# M367 register map
File version: 0.1
TOSHIBA Cortex-M3 MCU
Registers are 32-bit, read-write, reset 0x0 unless marked. A register's access mark holds for its fields unless they carry their own. Offsets are from the block's base; lines under a group give offsets from that group; [hi:lo] are bit positions; {n}, {i} and the like mark numbered series; 'fields as' and 'values as' point back to an identical list; <NAME> marks a mode.

## Memory map
0x40008000 UDFS blocks up to offset 0x8C — UDC2 AHB Bridge
0x40008200 UDFS2 blocks up to offset 0x338 — UDC2(USB -Spec2.0 Device contoller)
0x40040000 SSP0 size 0x28 — Synchronous Serial Port
0x40041000 SSP1 size 0x28
0x40042000 SSP2 size 0x28
0x40048000 UART4 blocks up to offset 0x4C — ARM Prime Cell PL011
0x40049000 UART5 blocks up to offset 0x4C
0x4004C000 DMAA blocks up to offset 0x50 — DMA Controller
0x4004D000 DMAB blocks up to offset 0x50
0x40050000 ADA blocks up to offset 0x78 — Analog-to-Digital Converter (AD)
0x40051000 ADB blocks up to offset 0x78 — Analog-to-Digital Converter (AD)
0x40052000 ADILV size 0xC — Dual ADC Configuration
0x40054000 DA0 size 0x14 — Digital-to-Analog Converter (DA)
0x40055000 DA1 size 0x14
0x4005C000 EXB blocks up to offset 0x50 — External Bus Interface(EXB)
0x400C0000 PA blocks up to offset 0x3C — General Purpose Input_Output Port (PA)
0x400C0100 PB blocks up to offset 0x3C — General Purpose Input_Output Port (PB)
0x400C0400 PE blocks up to offset 0x3C — General Purpose Input_Output Port (PE)
0x400C0500 PF blocks up to offset 0x3C — General Purpose Input_Output Port (PF)
0x400C0600 PG blocks up to offset 0x3C — General Purpose Input_Output Port (PG)
0x400C0700 PH blocks up to offset 0x3C — General Purpose Input_Output Port (PH)
0x400C0800 PI blocks up to offset 0x3C — General Purpose Input_Output Port (PI)
0x400C0A00 PK blocks up to offset 0x3C — General Purpose Input_Output Port (PK)
0x400C0B00 PL blocks up to offset 0x3C — General Purpose Input_Output Port (PL)
0x400C4000 TB0 size 0x34 — 16-bit Timer_Event Counter (TB)
0x400C4100 TB1 size 0x34
0x400C4200 TB2 size 0x34
0x400C4300 TB3 size 0x34
0x400C4400 TB4 size 0x34
0x400C4500 TB5 size 0x34
0x400C4600 TB6 size 0x34
0x400C4700 TB7 size 0x34
0x400C7000 MT0 size 0x58 — 16-bit Multi-Purpose Timer (MPT-TMR_IGBT)
0x400C7100 MT1 size 0x58
0x400C7200 MT2 size 0x58
0x400C7300 MT3 size 0x58
0x400CC000 RTC blocks up to offset 0xD — Real Time Clock (RTC)
0x400E0000 SBI0 size 0x18 — Serial Bus Interface (SBI)
0x400E0100 SBI1 size 0x18
0x400E0200 SBI2 size 0x18
0x400E1000 SC0 size 0x34 — Serial Channel (SC)
0x400E1100 SC1 size 0x34
0x400E1200 SC2 size 0x34
0x400E1300 SC3 size 0x34
0x400E7000 RMC size 0x38 — Remote Control Signal Preprocessor (RMC)
0x400F1000 OFD size 0x24 — Oscillation Frequency Detector (OFD)
0x400F2000 WD size 0x8 — Watchdog Timer (WD)
0x400F3000 CG blocks up to offset 0x6C — Clock Generator (CG)
0x400F3100 USBPLL size 0xC — Low Voltage detector control register
0x400F3200 TRMOSC size 0x10 — Low Voltage detector control register
0x400F4000 LVD size 0xC — Low Voltage detector control register
0x400F6000 MTPD blocks up to offset 0x48 — 16-bit Multi-Purpose Timer (MPT-PMD)
0x400F7000 EN size 0x10 — Encoder Input (ENC)
0x41FFF000 FC blocks up to offset 0x24 — Flash Control (FC)

## UDFS — UDC2 AHB Bridge
Base 0x40008000
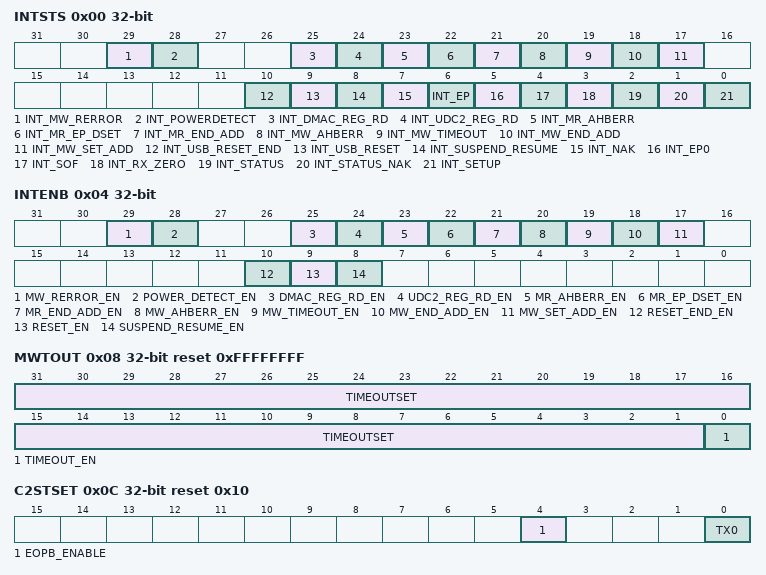
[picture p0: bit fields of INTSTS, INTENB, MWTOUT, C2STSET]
0x00 INTSTS — Interrupt Status Register
  [29] INT_MW_RERROR, [28] INT_POWERDETECT, [25] INT_DMAC_REG_RD, [24] INT_UDC2_REG_RD, [23] INT_MR_AHBERR, [22] INT_MR_EP_DSET, [21] INT_MR_END_ADD, [20] INT_MW_AHBERR, [19] INT_MW_TIMEOUT, [18] INT_MW_END_ADD, [17] INT_MW_SET_ADD, [10] INT_USB_RESET_END, [9] INT_USB_RESET, [8] INT_SUSPEND_RESUME, [7] INT_NAK ro, [6] INT_EP ro, [5] INT_EP0 ro, [4] INT_SOF ro, [3] INT_RX_ZERO ro, [2] INT_STATUS ro, [1] INT_STATUS_NAK ro, [0] INT_SETUP ro
0x04 INTENB — Interrupt Enable Register
  [29] MW_RERROR_EN, [28] POWER_DETECT_EN, [25] DMAC_REG_RD_EN, [24] UDC2_REG_RD_EN, [23] MR_AHBERR_EN, [22] MR_EP_DSET_EN, [21] MR_END_ADD_EN, [20] MW_AHBERR_EN, [19] MW_TIMEOUT_EN, [18] MW_END_ADD_EN, [17] MW_SET_ADD_EN, [10] RESET_END_EN, [9] RESET_EN, [8] SUSPEND_RESUME_EN
0x08 MWTOUT reset 0xFFFFFFFF — Master Write Timeout Register
  [31:1] TIMEOUTSET, [0] TIMEOUT_EN
0x0C C2STSET reset 0x10 — UDC2 setting
  [4] EOPB_ENABLE, [0] TX0
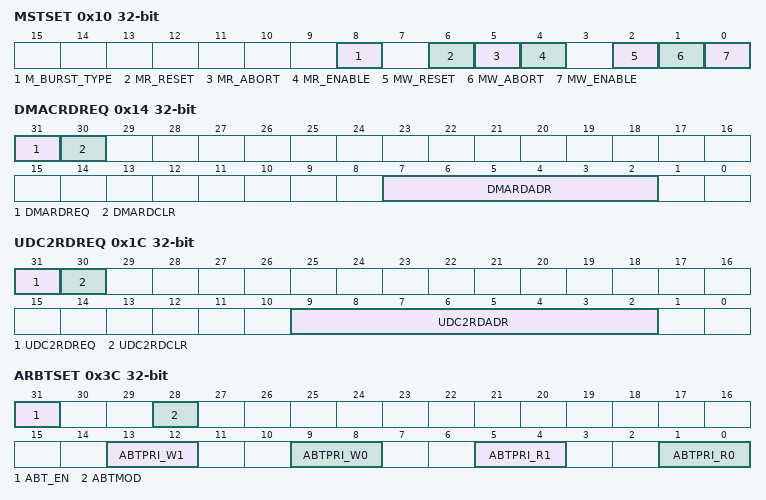
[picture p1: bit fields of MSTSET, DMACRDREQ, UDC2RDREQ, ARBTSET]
0x10 MSTSET — DMAC setting
  [8] M_BURST_TYPE, [6] MR_RESET, [5] MR_ABORT wo, [4] MR_ENABLE, [2] MW_RESET, [1] MW_ABORT wo, [0] MW_ENABLE
0x14 DMACRDREQ — DMAC Read request
  [31] DMARDREQ, [30] DMARDCLR, [7:2] DMARDADR
0x18 DMACRDVL ro — DMAC Read Value
  [31:0] DMARDDATA
0x1C UDC2RDREQ — UDC2 Read Request
  [31] UDC2RDREQ, [30] UDC2RDCLR, [9:2] UDC2RDADR
0x20 UDC2RDVL ro — UDC2 Read Value
  [15:0] UDC2RDATA
0x3C ARBTSET — Arbiter Setting
  [31] ABT_EN, [28] ABTMOD, [13:12] ABTPRI_W1, [9:8] ABTPRI_W0, [5:4] ABTPRI_R1 ro, [1:0] ABTPRI_R0
0x40 MWSADR reset 0xFFFFFFFF — Master Write Start Address
0x44 MWEADR reset 0xFFFFFFFF — Master Write End Address
0x48 MWCADR ro reset 0xFFFFFFFF — Master Write Current Address
0x4C MWAHBADR ro reset 0xFFFFFFFF — Master Write AHB Address
0x50 MRSADR reset 0xFFFFFFFF — Master Read Start Address
0x54 MREADR reset 0xFFFFFFFF — Master Read End Address
0x58 MRCADR ro reset 0xFFFFFFFF — Master Read Current Address
0x5C MRAHBADR ro reset 0xFFFFFFFF — Master Read AHB Address
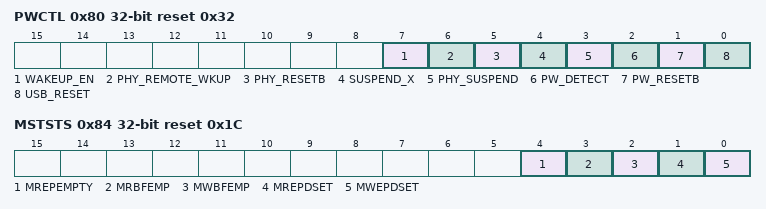
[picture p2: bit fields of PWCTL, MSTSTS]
0x80 PWCTL reset 0x32 — Power Detect Control
  [7] WAKEUP_EN, [6] PHY_REMOTE_WKUP, [5] PHY_RESETB, [4] SUSPEND_X ro, [3] PHY_SUSPEND, [2] PW_DETECT ro, [1] PW_RESETB, [0] USB_RESET ro
0x84 MSTSTS ro reset 0x1C — Master Status
  [4] MREPEMPTY, [3] MRBFEMP, [2] MWBFEMP, [1] MREPDSET, [0] MWEPDSET
0x88 TOUTCNT ro reset 0xFFFFFFFF — Timeout Count
  [31:0] TMOUTCNT
